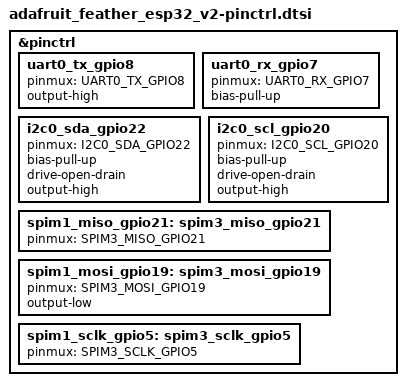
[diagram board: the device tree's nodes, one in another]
/*
 * Copyright (c) 2023 MIT Media Lab
 * SPDX-License-Identifier: Apache-2.0
 */

#include <zephyr/dt-bindings/pinctrl/esp-pinctrl-common.h>
#include <dt-bindings/pinctrl/esp32-pinctrl.h>
#include <zephyr/dt-bindings/pinctrl/esp32-gpio-sigmap.h>

&pinctrl {
	uart0_tx_gpio8: uart0_tx_gpio8 {
		pinmux = <UART0_TX_GPIO8>;
		output-high;
	};

	uart0_rx_gpio7: uart0_rx_gpio7 {
		pinmux = <UART0_RX_GPIO7>;
		bias-pull-up;
	};

	i2c0_sda_gpio22: i2c0_sda_gpio22 {
		pinmux = <I2C0_SDA_GPIO22>;
		bias-pull-up;
		drive-open-drain;
		output-high;
	};

	i2c0_scl_gpio20: i2c0_scl_gpio20 {
		pinmux = <I2C0_SCL_GPIO20>;
		bias-pull-up;
		drive-open-drain;
		output-high;
	};

	spim1_miso_gpio21: spim3_miso_gpio21 {
		pinmux = <SPIM3_MISO_GPIO21>;
	};

	spim1_mosi_gpio19: spim3_mosi_gpio19 {
		pinmux = <SPIM3_MOSI_GPIO19>;
		output-low;
	};

	spim1_sclk_gpio5: spim3_sclk_gpio5 {
		pinmux = <SPIM3_SCLK_GPIO5>;
	};
};
